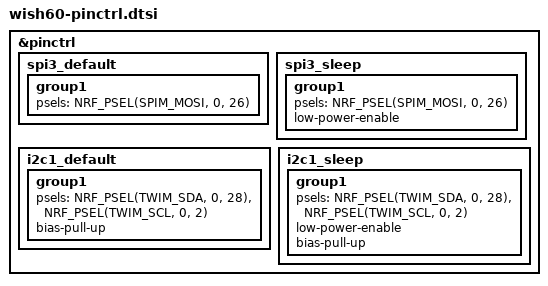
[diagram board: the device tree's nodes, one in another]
/*
 * Copyright (c) 2022 The ZMK Contributors
 * SPDX-License-Identifier: MIT
 */

&pinctrl {
    spi3_default: spi3_default {
        group1 {
            psels = <NRF_PSEL(SPIM_MOSI, 0, 26)>;
        };
    };

    spi3_sleep: spi3_sleep {
        group1 {
            psels = <NRF_PSEL(SPIM_MOSI, 0, 26)>;
            low-power-enable;
        };
    };

    i2c1_default: i2c1_default {
      group1 {
          psels = <NRF_PSEL(TWIM_SDA, 0, 28)>,
                  <NRF_PSEL(TWIM_SCL, 0, 2)>;
          bias-pull-up;
      };
    };

    i2c1_sleep: i2c1_sleep {
      group1 {
          psels = <NRF_PSEL(TWIM_SDA, 0, 28)>,
                  <NRF_PSEL(TWIM_SCL, 0, 2)>;
          low-power-enable;
          bias-pull-up;
      };
    };    
};
